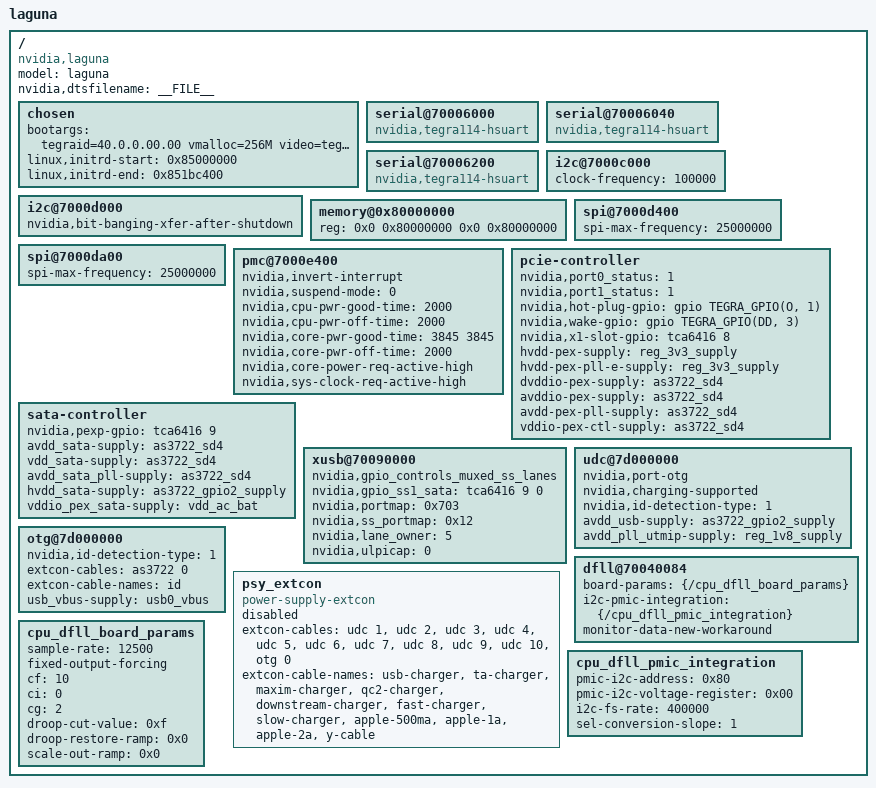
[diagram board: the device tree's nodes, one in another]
/dts-v1/;

#include "tegra132.dtsi"
#include "tegra124-platforms/tegra124-tn8-keys-e1780-1100-a02.dtsi"
#include "tegra124-platforms/tegra124-pm359-gpio-default.dtsi"
#include "tegra124-platforms/tegra124-pm359-pinmux.dtsi"
#include "tegra124-platforms/tegra124-pm359-pmic.dtsi"
#include "tegra124-platforms/tegra124-pm359-fixed.dtsi"

/ {
	model = "laguna";
	compatible = "nvidia,laguna", "nvidia,tegra132";
	nvidia,dtsfilename = __FILE__;
	#address-cells = <2>;
	#size-cells = <2>;

	chosen {
		bootargs = "tegraid=40.0.0.00.00 vmalloc=256M video=tegrafb console=ttyS0,115200n8 earlyprintk";
		linux,initrd-start = <0x85000000>;
		linux,initrd-end = <0x851bc400>;
	};

	serial@70006000 {
		compatible = "nvidia,tegra114-hsuart";
		status = "okay";
        };

	serial@70006040 {
		compatible = "nvidia,tegra114-hsuart";
		status = "okay";
	};

	serial@70006200 {
		compatible = "nvidia,tegra114-hsuart";
		status = "okay";
	};

	i2c@7000c000 {
		clock-frequency = <100000>;
	};

	i2c@7000d000 {
		nvidia,bit-banging-xfer-after-shutdown;
	};

	memory@0x80000000 {
		device_type = "memory";
		reg = <0x0 0x80000000 0x0 0x80000000>;
	};

	spi@7000d400 {
		status = "okay";
		spi-max-frequency = <25000000>;
	};

	spi@7000da00 {
		status = "okay";
		spi-max-frequency = <25000000>;
	};

	pmc@7000e400 {
		status = "okay";
		nvidia,invert-interrupt;
		nvidia,suspend-mode = <0>;
		nvidia,cpu-pwr-good-time = <2000>;
		nvidia,cpu-pwr-off-time = <2000>;
		nvidia,core-pwr-good-time = <3845 3845>;
		nvidia,core-pwr-off-time = <2000>;
		nvidia,core-power-req-active-high;
		nvidia,sys-clock-req-active-high;
	};

	pcie-controller {
		nvidia,port0_status = <1>;
		nvidia,port1_status = <1>;
		nvidia,hot-plug-gpio = <&gpio TEGRA_GPIO(O, 1) 0>;
		nvidia,wake-gpio = <&gpio TEGRA_GPIO(DD, 3) 0>;
		nvidia,x1-slot-gpio = <&tca6416 8 0>;
		hvdd-pex-supply = <&reg_3v3_supply>;
		hvdd-pex-pll-e-supply = <&reg_3v3_supply>;
		dvddio-pex-supply = <&as3722_sd4>;
		avddio-pex-supply = <&as3722_sd4>;
		avdd-pex-pll-supply = <&as3722_sd4>;
		vddio-pex-ctl-supply = <&as3722_sd4>;
		status = "okay";
	};

	sata-controller {
		nvidia,pexp-gpio = <&tca6416 9 0>;
		status = "okay";
		avdd_sata-supply = <&as3722_sd4>;
		vdd_sata-supply = <&as3722_sd4>;
		avdd_sata_pll-supply =<&as3722_sd4>;
		hvdd_sata-supply = <&as3722_gpio2_supply>;
		vddio_pex_sata-supply = <&vdd_ac_bat>;
	};

        xusb@70090000 {
		/* nvidia,uses_external_pmic; */
		nvidia,gpio_controls_muxed_ss_lanes;
		nvidia,gpio_ss1_sata = <&tca6416 9 0>;
		nvidia,portmap = <0x703>; /* SSP0,SSP1, USB2P0, USB2P1, USB2P2 */
		nvidia,ss_portmap = /bits/ 8 <0x12>; /* SSP0 on USB2P2 and SSP1 on USP2P1 */
		nvidia,lane_owner = /bits/ 8 <5>; /* USB3P0 USB3S0 and PCIe_X4 */
		nvidia,ulpicap = /bits/ 8 <0>; /* No ulpi support. can we remove */
		status = "okay";
	};

	udc@7d000000 {
		nvidia,port-otg;
		nvidia,charging-supported;
		nvidia,id-detection-type = <1>;
		#extcon-cells = <1>;
		avdd_usb-supply = <&as3722_gpio2_supply>;
		avdd_pll_utmip-supply = <&reg_1v8_supply>;
		status = "okay";
	};

	otg@7d000000 {
		nvidia,id-detection-type = <1>;
		extcon-cables = <&as3722 0>;
		extcon-cable-names = "id";
		#extcon-cells = <1>;
		usb_vbus-supply = <&usb0_vbus>;
		status = "okay";
	};

	psy_extcon {
		compatible = "power-supply-extcon";
		status = "disabled";
		extcon-cables = <&udc 1 &udc 2 &udc 3
				&udc 4 &udc 5 &udc 6
				&udc 7 &udc 8 &udc 9
				&udc 10 &otg 0>;
		extcon-cable-names = "usb-charger", "ta-charger", "maxim-charger",
				"qc2-charger", "downstream-charger","fast-charger",
				"slow-charger", "apple-500ma", "apple-1a",
				"apple-2a", "y-cable";
	};

	dfll@70040084 {
		board-params = <&{/cpu_dfll_board_params}>;
		i2c-pmic-integration = <&{/cpu_dfll_pmic_integration}>;
		monitor-data-new-workaround;
		status = "okay";
	};

	cpu_dfll_board_params {
		sample-rate = <12500>;
		fixed-output-forcing;
		cf = <10>;
		ci = <0>;
		cg = <2>;
		droop-cut-value = <0xf>;
		droop-restore-ramp = <0x0>;
		scale-out-ramp = <0x0>;
	};

	cpu_dfll_pmic_integration {
		pmic-i2c-address = <0x80>;
		pmic-i2c-voltage-register = <0x00>;
		i2c-fs-rate = <400000>;
		sel-conversion-slope = <1>;
	};
};
